# STM32WL3Rx register map
File version: 1.0
Registers are 32-bit, read-write, reset 0x0 unless marked. A register's access mark holds for its fields unless they carry their own. Offsets are from the block's base; [hi:lo] are bit positions; {n}, {i} and the like mark numbered series.

## DMAMUX1 — DMA Multiplexer
Base 0x48800000
0x00 CxCR — DMA Multiplexer Channel x Control Register
  [4:0] DMAREQ_ID
{0x0+4i} C{i}CR (i=1..7) — DMA Multiplexer Channel x Control Register
  [4:0] DMAREQ_ID

## AES — Advanced encryption standard hardware accelerator (AES)
Base 0x48900000
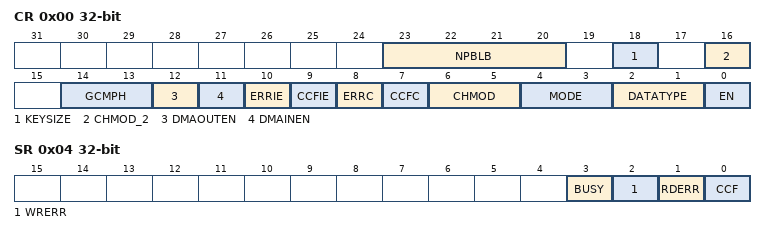
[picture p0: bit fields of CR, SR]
0x00 CR — (@ 0x00000000) Control Register
  [23:20] NPBLB, [18] KEYSIZE, [16] CHMOD_2, [14:13] GCMPH, [12] DMAOUTEN, [11] DMAINEN, [10] ERRIE, [9] CCFIE, [8] ERRC, [7] CCFC, [6:5] CHMOD, [4:3] MODE, [2:1] DATATYPE, [0] EN
0x04 SR — (@ 0x00000004) Status Register
  [3] BUSY, [2] WRERR, [1] RDERR, [0] CCF
0x08 DINR — (@ 0x00000008) Data Input register
0x0C DOUTR — (@ 0x0000000C) Data Output register
{0x10+4i} KEYR{i} (i=0..3) — (@ {0x10+4i}) Key register {i}
  [31:0] KEY
{0x20+4i} IVR{i} (i=0..3) — (@ {0x20+4i}) Initialization vector register {i}
  [31:0] IVI
{0x20+4i} KEYR{i} (i=4..7) — (@ {0x20+4i}) Key register {i}
  [31:0] KEY
{0x40+4i} SUSP{i} (i=0..7) — (@ {0x40+4i}) Suspend register {i}
  [31:0] SUSP

## MR_SUBG_GLOB_STATIC — MR_SUBG Global Static
Base 0x49000400
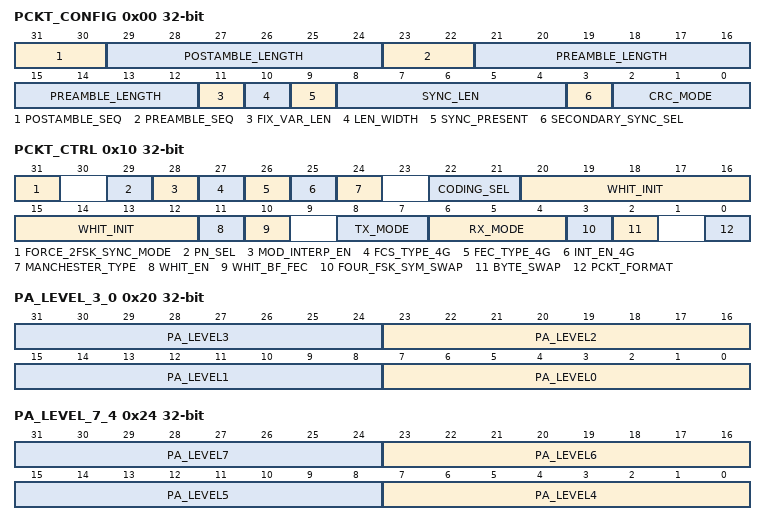
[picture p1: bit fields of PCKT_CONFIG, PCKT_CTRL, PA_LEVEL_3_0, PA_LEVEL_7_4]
0x00 PCKT_CONFIG — (@ 0x00000000) PCKT_CONFIG register
  [31:30] POSTAMBLE_SEQ, [29:24] POSTAMBLE_LENGTH, [23:22] PREAMBLE_SEQ, [21:12] PREAMBLE_LENGTH, [11] FIX_VAR_LEN, [10] LEN_WIDTH, [9] SYNC_PRESENT, [8:4] SYNC_LEN, [3] SECONDARY_SYNC_SEL, [2:0] CRC_MODE
0x04 SYNC — (@ 0x00000004) SYNC register
0x08 SEC_SYNC — (@ 0x00000008) SEC_SYNC register
0x0C CRC_INIT — (@ 0x0000000C) CRC_INIT register
  [31:0] CRC_INIT_VAL
0x10 PCKT_CTRL — (@ 0x00000010) PCKT_CTRL register
  [31] FORCE_2FSK_SYNC_MODE, [29] PN_SEL, [28] MOD_INTERP_EN, [27] FCS_TYPE_4G, [26] FEC_TYPE_4G, [25] INT_EN_4G, [24] MANCHESTER_TYPE, [22:21] CODING_SEL, [20:12] WHIT_INIT, [11] WHIT_EN, [10] WHIT_BF_FEC, [8:7] TX_MODE, [6:4] RX_MODE, [3] FOUR_FSK_SYM_SWAP, [2] BYTE_SWAP, [0] PCKT_FORMAT
0x14 DATABUFFER0_PTR — (@ 0x00000014) DATABUFFER0_PTR register
  [31:2] DATABUFFER0_PTR
0x18 DATABUFFER1_PTR — (@ 0x00000018) DATABUFFER1_PTR register
  [31:2] DATABUFFER1_PTR
0x1C DATABUFFER_SIZE — (@ 0x0000001C) DATABUFFER_SIZE register
  [15:0] DATABUFFER_SIZE
0x20 PA_LEVEL_3_0 — (@ 0x00000020) PA_LEVEL_3_0 register
  [8n+7:8n] PA_LEVEL{n} (n=0..3)
0x24 PA_LEVEL_7_4 — (@ 0x00000024) PA_LEVEL_7_4 register
  [8n-25:8n-32] PA_LEVEL{n} (n=4..7)
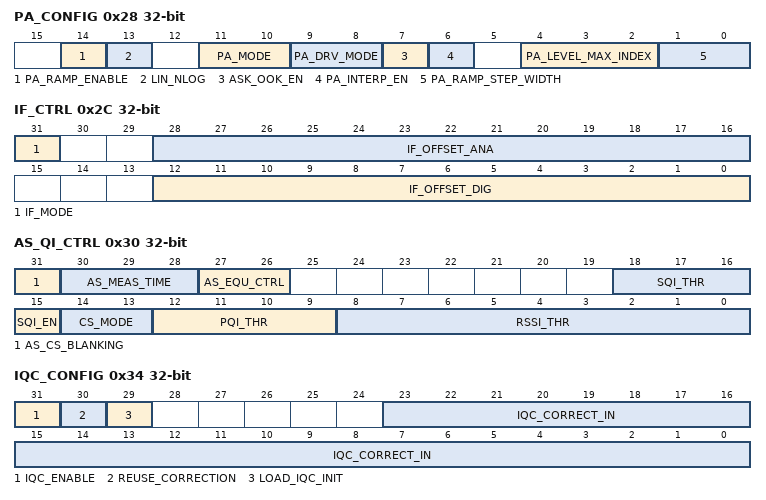
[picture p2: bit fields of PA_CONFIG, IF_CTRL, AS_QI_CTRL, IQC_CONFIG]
0x28 PA_CONFIG — (@ 0x00000028) PA_CONFIG register
  [14] PA_RAMP_ENABLE, [13] LIN_NLOG, [11:10] PA_MODE, [9:8] PA_DRV_MODE, [7] ASK_OOK_EN, [6] PA_INTERP_EN, [4:2] PA_LEVEL_MAX_INDEX, [1:0] PA_RAMP_STEP_WIDTH
0x2C IF_CTRL — (@ 0x0000002C) IF_CTRL register
  [31] IF_MODE, [28:16] IF_OFFSET_ANA, [12:0] IF_OFFSET_DIG
0x30 AS_QI_CTRL — (@ 0x00000030) AS_QI_CTRL register
  [31] AS_CS_BLANKING, [30:28] AS_MEAS_TIME, [27:26] AS_EQU_CTRL, [18:16] SQI_THR, [15] SQI_EN, [14:13] CS_MODE, [12:9] PQI_THR, [8:0] RSSI_THR
0x34 IQC_CONFIG — (@ 0x00000034) IQC_CONFIG register
  [31] IQC_ENABLE, [30] REUSE_CORRECTION, [29] LOAD_IQC_INIT, [23:0] IQC_CORRECT_IN
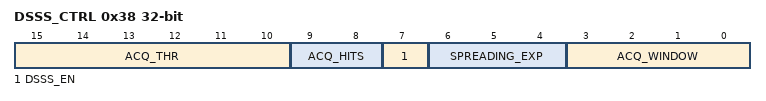
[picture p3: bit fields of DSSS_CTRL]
0x38 DSSS_CTRL — (@ 0x00000038) DSSS_CTRL register
  [15:10] ACQ_THR, [9:8] ACQ_HITS, [7] DSSS_EN, [6:4] SPREADING_EXP, [3:0] ACQ_WINDOW

## MR_SUBG_GLOB_DYNAMIC — MR_SUBG Global Dynamic
Base 0x49000500
0x00 PCKTLEN_CONFIG — (@ 0x00000000) PCKTLEN_CONFIG register
  [15:0] PCKTLEN
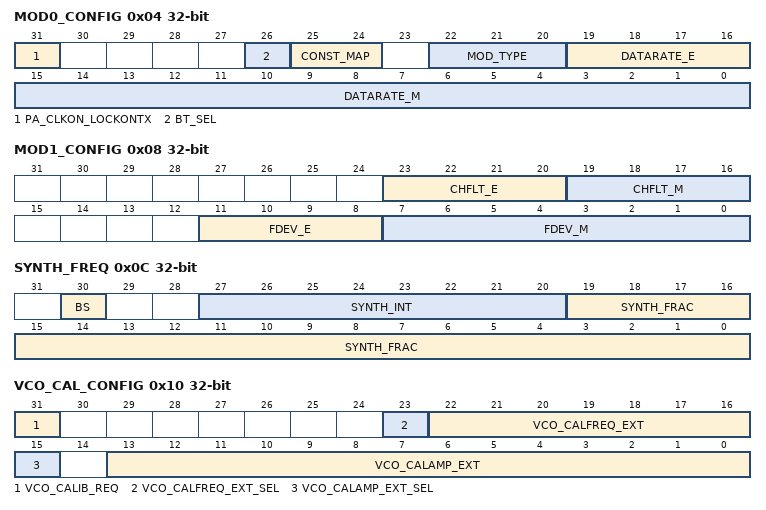
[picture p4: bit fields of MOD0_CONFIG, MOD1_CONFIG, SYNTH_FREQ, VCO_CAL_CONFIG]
0x04 MOD0_CONFIG — (@ 0x00000004) MOD0_CONFIG register
  [31] PA_CLKON_LOCKONTX, [26] BT_SEL, [25:24] CONST_MAP, [22:20] MOD_TYPE, [19:16] DATARATE_E, [15:0] DATARATE_M
0x08 MOD1_CONFIG — (@ 0x00000008) MOD1_CONFIG register
  [23:20] CHFLT_E, [19:16] CHFLT_M, [11:8] FDEV_E, [7:0] FDEV_M
0x0C SYNTH_FREQ — (@ 0x0000000C) SYNTH_FREQ register
  [30] BS, [27:20] SYNTH_INT, [19:0] SYNTH_FRAC
0x10 VCO_CAL_CONFIG — (@ 0x00000010) VCO_CAL_CONFIG register
  [31] VCO_CALIB_REQ, [23] VCO_CALFREQ_EXT_SEL, [22:16] VCO_CALFREQ_EXT, [15] VCO_CALAMP_EXT_SEL, [13:0] VCO_CALAMP_EXT
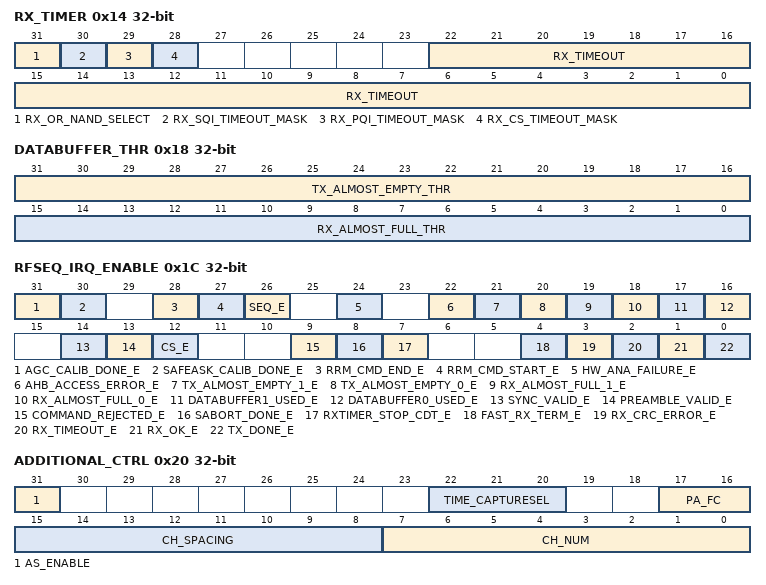
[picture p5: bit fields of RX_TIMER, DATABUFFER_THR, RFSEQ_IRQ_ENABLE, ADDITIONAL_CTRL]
0x14 RX_TIMER — (@ 0x00000014) RX_TIMER register
  [31] RX_OR_NAND_SELECT, [30] RX_SQI_TIMEOUT_MASK, [29] RX_PQI_TIMEOUT_MASK, [28] RX_CS_TIMEOUT_MASK, [22:0] RX_TIMEOUT
0x18 DATABUFFER_THR — (@ 0x00000018) DATABUFFER_THR register
  [31:16] TX_ALMOST_EMPTY_THR, [15:0] RX_ALMOST_FULL_THR
0x1C RFSEQ_IRQ_ENABLE — (@ 0x0000001C) RFSEQ_IRQ_ENABLE register
  [31] AGC_CALIB_DONE_E, [30] SAFEASK_CALIB_DONE_E, [28] RRM_CMD_END_E, [27] RRM_CMD_START_E, [26] SEQ_E, [24] HW_ANA_FAILURE_E, [22] AHB_ACCESS_ERROR_E, [21] TX_ALMOST_EMPTY_1_E, [20] TX_ALMOST_EMPTY_0_E, [19] RX_ALMOST_FULL_1_E, [18] RX_ALMOST_FULL_0_E, [17] DATABUFFER1_USED_E, [16] DATABUFFER0_USED_E, [14] SYNC_VALID_E, [13] PREAMBLE_VALID_E, [12] CS_E, [9] COMMAND_REJECTED_E, [8] SABORT_DONE_E, [7] RXTIMER_STOP_CDT_E, [4] FAST_RX_TERM_E, [3] RX_CRC_ERROR_E, [2] RX_TIMEOUT_E, [1] RX_OK_E, [0] TX_DONE_E
0x20 ADDITIONAL_CTRL — (@ 0x00000020) ADDITIONAL_CTRL register
  [31] AS_ENABLE, [22:20] TIME_CAPTURESEL, [17:16] PA_FC, [15:8] CH_SPACING, [7:0] CH_NUM
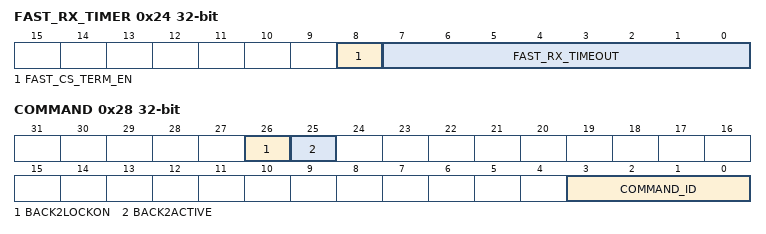
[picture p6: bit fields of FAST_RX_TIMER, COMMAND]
0x24 FAST_RX_TIMER — (@ 0x00000024) FAST_RX_TIMER register
  [8] FAST_CS_TERM_EN, [7:0] FAST_RX_TIMEOUT
0x28 COMMAND — (@ 0x00000028) COMMAND register
  [26] BACK2LOCKON, [25] BACK2ACTIVE, [3:0] COMMAND_ID

## MR_SUBG_GLOB_STATUS — MR_SUBG Global Status
Base 0x49000600
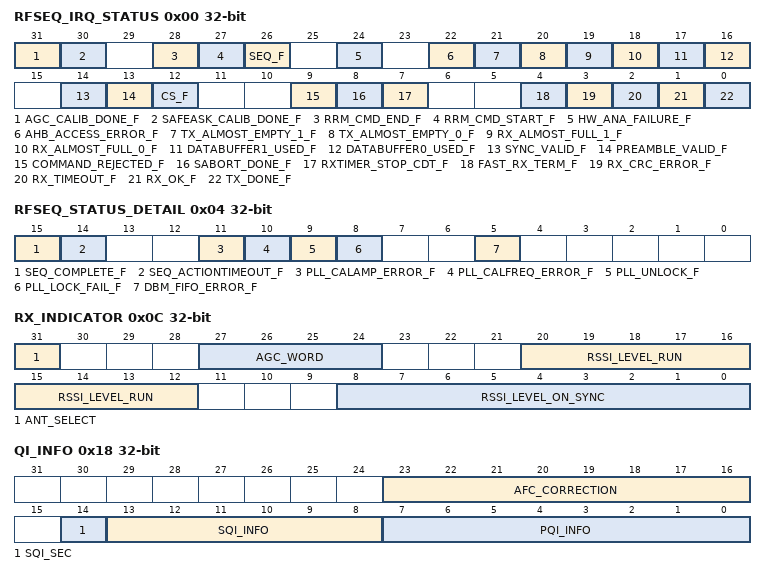
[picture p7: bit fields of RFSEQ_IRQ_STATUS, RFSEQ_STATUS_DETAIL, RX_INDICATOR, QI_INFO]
0x00 RFSEQ_IRQ_STATUS — (@ 0x00000000) RFSEQ_IRQ_STATUS register
  [31] AGC_CALIB_DONE_F, [30] SAFEASK_CALIB_DONE_F, [28] RRM_CMD_END_F, [27] RRM_CMD_START_F, [26] SEQ_F, [24] HW_ANA_FAILURE_F, [22] AHB_ACCESS_ERROR_F, [21] TX_ALMOST_EMPTY_1_F, [20] TX_ALMOST_EMPTY_0_F, [19] RX_ALMOST_FULL_1_F, [18] RX_ALMOST_FULL_0_F, [17] DATABUFFER1_USED_F, [16] DATABUFFER0_USED_F, [14] SYNC_VALID_F, [13] PREAMBLE_VALID_F, [12] CS_F, [9] COMMAND_REJECTED_F, [8] SABORT_DONE_F, [7] RXTIMER_STOP_CDT_F, [4] FAST_RX_TERM_F, [3] RX_CRC_ERROR_F, [2] RX_TIMEOUT_F, [1] RX_OK_F, [0] TX_DONE_F
0x04 RFSEQ_STATUS_DETAIL — (@ 0x00000004) RFSEQ_STATUS_DETAIL register
  [15] SEQ_COMPLETE_F, [14] SEQ_ACTIONTIMEOUT_F, [11] PLL_CALAMP_ERROR_F, [10] PLL_CALFREQ_ERROR_F, [9] PLL_UNLOCK_F, [8] PLL_LOCK_FAIL_F, [5] DBM_FIFO_ERROR_F
0x08 RADIO_FSM_INFO — (@ 0x00000008) RADIO_FSM_INFO register
  [4:0] RADIO_FSM_STATE
0x0C RX_INDICATOR — (@ 0x0000000C) RX_INDICATOR register
  [31] ANT_SELECT, [27:24] AGC_WORD, [20:12] RSSI_LEVEL_RUN, [8:0] RSSI_LEVEL_ON_SYNC
0x10 RX_INFO_REG — (@ 0x00000010) RX_INFO_REG register
  [15:0] RX_PCKTLEN_OUT
0x14 RX_CRC_REG — (@ 0x00000014) RX_CRC_REG register
  [31:0] RX_CRC_OUT
0x18 QI_INFO — (@ 0x00000018) QI_INFO register
  [23:16] AFC_CORRECTION, [14] SQI_SEC, [13:8] SQI_INFO, [7:0] PQI_INFO
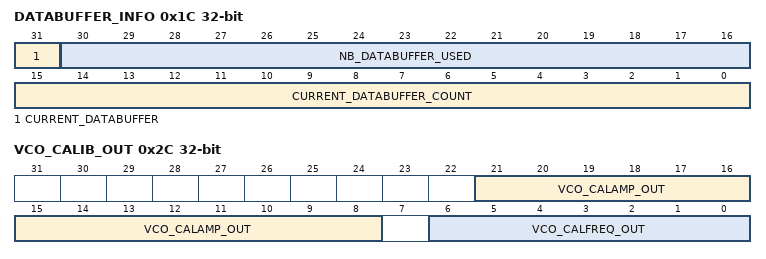
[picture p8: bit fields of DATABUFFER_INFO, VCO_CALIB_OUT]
0x1C DATABUFFER_INFO — (@ 0x0000001C) DATABUFFER_INFO register
  [31] CURRENT_DATABUFFER, [30:16] NB_DATABUFFER_USED, [15:0] CURRENT_DATABUFFER_COUNT
0x20 TIME_CAPTURE — (@ 0x00000020) TIME_CAPTURE register
0x24 IQC_CORRECTION_OUT — (@ 0x00000024) IQC_CORRECTION_OUT register
  [23:0] IQC_CORRECT_OUT
0x28 PA_SAFEASK_OUT — (@ 0x00000028) PA_SAFEASK_OUT register
  [7:0] PA_CODEMAX
0x2C VCO_CALIB_OUT — (@ 0x0000002C) VCO_CALIB_OUT register
  [21:8] VCO_CALAMP_OUT, [6:0] VCO_CALFREQ_OUT
0x30 SEQ_INFO — (@ 0x00000030) SEQ_INFO register
  [4:0] SEQ_FSM_STATE
0x34 SEQ_EVENT_STATUS — (@ 0x00000034) SEQ_EVENT_STATUS register

## MR_SUBG_GLOB_MISC — MR_SUBG Global Misc
Base 0x49000700
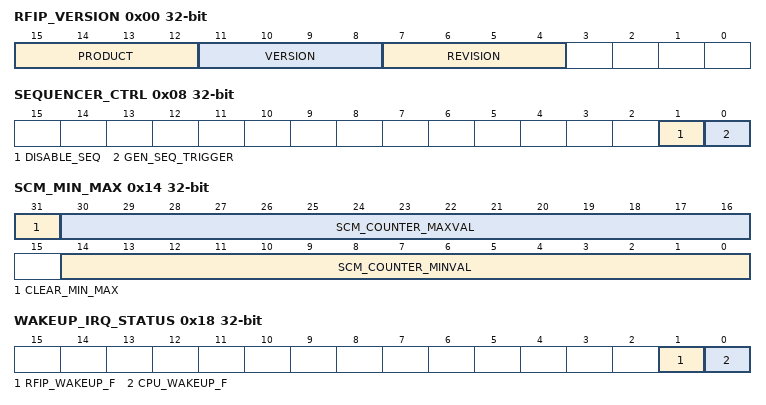
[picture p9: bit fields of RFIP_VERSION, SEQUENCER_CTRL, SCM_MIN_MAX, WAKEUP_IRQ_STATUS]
0x00 RFIP_VERSION — (@ 0x00000000) RFIP_VERSION register
  [15:12] PRODUCT, [11:8] VERSION, [7:4] REVISION
0x04 RRM_UDRA_CTRL — (@ 0x00000004) RRM_UDRA_CTRL register
  [0] RRM_CMD_REQ
0x08 SEQUENCER_CTRL — (@ 0x00000008) SEQUENCER_CTRL register
  [1] DISABLE_SEQ, [0] GEN_SEQ_TRIGGER
0x0C ABSOLUTE_TIME — (@ 0x0000000C) ABSOLUTE_TIME register
0x10 SCM_COUNTER_VAL — (@ 0x00000010) SCM_COUNTER_VAL register
  [14:0] SCM_COUNTER_CURRVAL
0x14 SCM_MIN_MAX — (@ 0x00000014) SCM_MIN_MAX register
  [31] CLEAR_MIN_MAX, [30:16] SCM_COUNTER_MAXVAL, [14:0] SCM_COUNTER_MINVAL
0x18 WAKEUP_IRQ_STATUS — (@ 0x00000018) WAKEUP_IRQ_STATUS register
  [1] RFIP_WAKEUP_F, [0] CPU_WAKEUP_F

## MR_SUBG_GLOB_RETAINED — MR_SUBG Global Retained
Base 0x49000780
0x00 RFIP_WAKEUPTIME — (@ 0x00000000) RFIP_WAKEUPTIME register
0x04 CPU_WAKEUPTIME — (@ 0x00000004) CPU_WAKEUPTIME register
  [31:1] CPU_WAKEUPTIME
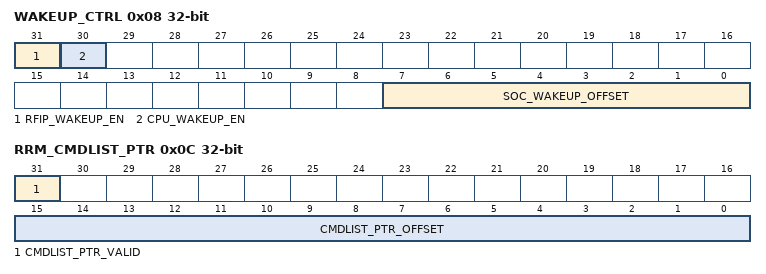
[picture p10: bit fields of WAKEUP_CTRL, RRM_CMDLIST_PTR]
0x08 WAKEUP_CTRL — (@ 0x00000008) WAKEUP_CTRL register
  [31] RFIP_WAKEUP_EN, [30] CPU_WAKEUP_EN, [7:0] SOC_WAKEUP_OFFSET
0x0C RRM_CMDLIST_PTR — (@ 0x0000000C) RRM_CMDLIST_PTR register
  [31] CMDLIST_PTR_VALID, [15:0] CMDLIST_PTR_OFFSET
0x10 SEQ_GLOBALTABLE_PTR — (@ 0x00000010) SEQ_GLOBALTABLE_PTR register
  [15:0] SEQ_GLOBALTABLE_PTR
